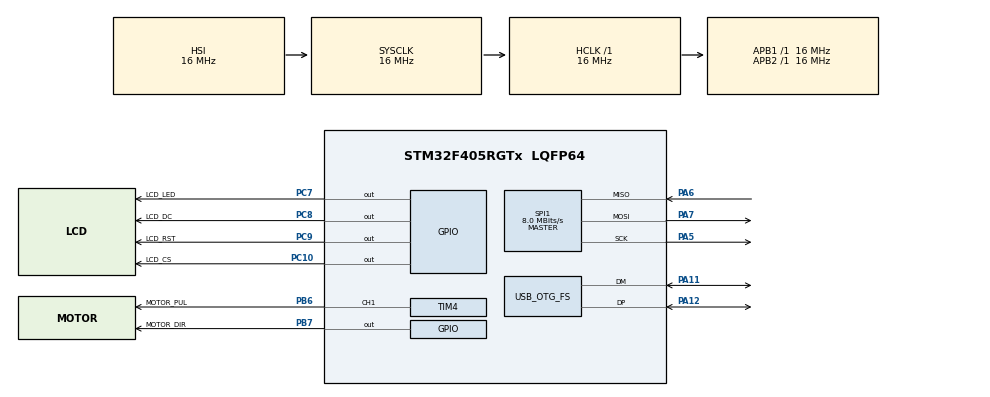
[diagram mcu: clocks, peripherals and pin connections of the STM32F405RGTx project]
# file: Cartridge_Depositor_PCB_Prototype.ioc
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Mcu.Family=STM32F4
TIM4.Channel-PWM\ Generation1\ CH1=TIM_CHANNEL_1
PA6.Mode=Full_Duplex_Master
USB_DEVICE.CLASS_NAME_FS=CDC
PH0-OSC_IN.Signal=RCC_OSC_IN
RCC.CortexFreq_Value=16000000
PA7.Mode=Full_Duplex_Master
PC10.GPIO_Label=LCD_CS
SPI1.VirtualType=VM_MASTER
PC9.GPIO_Label=LCD_RST
USB_DEVICE.VirtualModeFS=Cdc_FS
PC10.Signal=GPIO_Output
PC8.Signal=GPIO_Output
PA11.Mode=Device_Only
PB6.GPIO_Label=MOTOR_PUL
USB_DEVICE.VirtualMode-CDC_FS=Cdc
ProjectManager.StackSize=0x400
PC8.GPIO_Label=LCD_DC
PA13.Signal=SYS_JTMS-SWDIO
PA12.Signal=USB_OTG_FS_DP
ProjectManager.TargetToolchain=STM32CubeIDE
SPI1.Direction=SPI_DIRECTION_2LINES
RCC.HCLKFreq_Value=16000000
VP_USB_DEVICE_VS_USB_DEVICE_CDC_FS.Mode=CDC_FS
RCC.APB2TimFreq_Value=16000000
TIM4.Pulse-PWM\ Generation1\ CH1=50-1
PB6.Signal=S_TIM4_CH1
PC7.Signal=GPIO_Output
SPI1.CalculateBaudRate=8.0 MBits/s
TIM4.Prescaler=80-1
RCC.LSE_VALUE=32768
RCC.AHBFreq_Value=16000000
PH0-OSC_IN.Mode=HSE-External-Oscillator
PA5.Signal=SPI1_SCK
RCC.HSE_VALUE=25000000
board=custom
RCC.VCOOutputFreq_Value=240000000
RCC.APB2Freq_Value=16000000
SPI1.Mode=SPI_MODE_MASTER
PA14.Mode=Serial_Wire
PC7.PinState=GPIO_PIN_SET
PH1-OSC_OUT.Signal=RCC_OSC_OUT
PB7.Signal=GPIO_Output
TIM4.Period=50-1
PA13.Mode=Serial_Wire
Mcu.Name=STM32F405RGTx
PC7.GPIO_Label=LCD_LED
PH1-OSC_OUT.Mode=HSE-External-Oscillator
PB7.GPIO_Label=MOTOR_DIR
RCC.48MHZClocksFreq_Value=48000000
RCC.SYSCLKFreq_VALUE=16000000
Mcu.Package=LQFP64
PA6.Signal=SPI1_MISO
PA12.Mode=Device_Only
NVIC.OTG_FS_IRQn=true\:0\:0\:false\:false\:true\:false\:true
PA11.Signal=USB_OTG_FS_DM
PA14.Signal=SYS_JTCK-SWCLK
USB_OTG_FS.VirtualMode=Device_Only
ProjectManager.HeapSize=0x200
RCC.HSI_VALUE=16000000
VP_TIM4_VS_ClockSourceINT.Mode=Internal
RCC.PLLQ=5
NVIC.PriorityGroup=NVIC_PRIORITYGROUP_4
RCC.PLLM=15
RCC.PLLN=144
SH.S_TIM4_CH1.0=TIM4_CH1,PWM Generation1 CH1
RCC.APB1TimFreq_Value=16000000
PC9.Signal=GPIO_Output
RCC.APB1Freq_Value=16000000
PA5.Mode=Full_Duplex_Master
PA7.Signal=SPI1_MOSI

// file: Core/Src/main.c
/* USER CODE BEGIN Header */
/**
  ******************************************************************************
  * @file           : main.c
  * @brief          : Main program body
  ******************************************************************************
  * @attention
  *
  * <h2><center>&copy; Copyright (c) 2021 STMicroelectronics.
  * All rights reserved.</center></h2>
  *
  * This software component is licensed by ST under BSD 3-Clause license,
  * the "License"; You may not use this file except in compliance with the
  * License. You may obtain a copy of the License at:
  *                        opensource.org/licenses/BSD-3-Clause
  *
  ******************************************************************************
  */
/* USER CODE END Header */
#include "main.h"
#include "usb_device.h"

/* USER CODE BEGIN Includes */
#include "MY_ILI9341.h"
#include "TSC2046.h"
#include "Gui.h"
#include "motor_driver.h"
/* USER CODE END Includes */

/* USER CODE BEGIN PM */
#define CAL_MODE 0

/* USER CODE END PM */

SPI_HandleTypeDef hspi1;

TIM_HandleTypeDef htim4;

void SystemClock_Config(void);
static void MX_GPIO_Init(void);
static void MX_SPI1_Init(void);
static void MX_TIM4_Init(void);

int main(void)
{

  /* MCU Configuration--------------------------------------------------------*/

  /* Reset of all peripherals, Initializes the Flash interface and the Systick. */
  HAL_Init();
uint8_t i;

  /* Configure the system clock */
  SystemClock_Config();

  /* Initialize all configured peripherals */
  MX_GPIO_Init();
  MX_SPI1_Init();
  MX_USB_DEVICE_Init();
  MX_TIM4_Init();
  /* USER CODE BEGIN 2 */
  ILI9341_Init(&hspi1, LCD_CS_GPIO_Port, LCD_CS_Pin, LCD_DC_GPIO_Port, LCD_DC_Pin, LCD_RST_GPIO_Port, LCD_RST_Pin);
  HAL_GPIO_WritePin(LCD_LED_GPIO_Port, LCD_LED_Pin, 1); //Keeps screen on
  ILI9341_setRotation(1); //Rotation vertical, pins at top
  //TSC2046_Begin(&hspi2, TS_CS_GPIO_Port, TS_CS_Pin);
  ILI9341_Fill(COLOR_BLUE);
  ILI9341_printText("Hello World", 20, 40, COLOR_WHITE, COLOR_BLACK, 2);
  HAL_GPIO_WritePin(MOTOR_DIR_GPIO_Port, MOTOR_DIR_Pin, GPIO_PIN_RESET); //Initialize motor direction to CW
  HAL_TIM_PWM_Start(&htim4, TIM_CHANNEL_1); //Start motor pulse

  /* USER CODE END 2 */

  /*
  if(CAL_MODE)
    {
    TSC2046_Calibrate();
    ILI9341_Fill(COLOR_WHITE);
    Print_Cal_Vals();
    }
  else
  	{
  	Set_Cal_Vals();
  	}
  */

  /* Infinite loop */
  while (1)
  {

    /* USER CODE BEGIN 3 */
	Manual_Mode();

  }
  /* USER CODE END 3 */
}

void SystemClock_Config(void)
{
  RCC_OscInitTypeDef RCC_OscInitStruct = {0};
  RCC_ClkInitTypeDef RCC_ClkInitStruct = {0};

  /** Configure the main internal regulator output voltage
  */
  __HAL_RCC_PWR_CLK_ENABLE();
  __HAL_PWR_VOLTAGESCALING_CONFIG(PWR_REGULATOR_VOLTAGE_SCALE1);
  /** Initializes the RCC Oscillators according to the specified parameters
  * in the RCC_OscInitTypeDef structure.
  */
  RCC_OscInitStruct.OscillatorType = RCC_OSCILLATORTYPE_HSI|RCC_OSCILLATORTYPE_HSE;
  RCC_OscInitStruct.HSEState = RCC_HSE_ON;
  RCC_OscInitStruct.HSIState = RCC_HSI_ON;
  RCC_OscInitStruct.HSICalibrationValue = RCC_HSICALIBRATION_DEFAULT;
  RCC_OscInitStruct.PLL.PLLState = RCC_PLL_ON;
  RCC_OscInitStruct.PLL.PLLSource = RCC_PLLSOURCE_HSE;
  RCC_OscInitStruct.PLL.PLLM = 15;
  RCC_OscInitStruct.PLL.PLLN = 144;
  RCC_OscInitStruct.PLL.PLLP = RCC_PLLP_DIV2;
  RCC_OscInitStruct.PLL.PLLQ = 5;
  if (HAL_RCC_OscConfig(&RCC_OscInitStruct) != HAL_OK)
  {
    Error_Handler();
  }
  /** Initializes the CPU, AHB and APB buses clocks
  */
  RCC_ClkInitStruct.ClockType = RCC_CLOCKTYPE_HCLK|RCC_CLOCKTYPE_SYSCLK
                              |RCC_CLOCKTYPE_PCLK1|RCC_CLOCKTYPE_PCLK2;
  RCC_ClkInitStruct.SYSCLKSource = RCC_SYSCLKSOURCE_HSI;
  RCC_ClkInitStruct.AHBCLKDivider = RCC_SYSCLK_DIV1;
  RCC_ClkInitStruct.APB1CLKDivider = RCC_HCLK_DIV1;
  RCC_ClkInitStruct.APB2CLKDivider = RCC_HCLK_DIV1;

  if (HAL_RCC_ClockConfig(&RCC_ClkInitStruct, FLASH_LATENCY_0) != HAL_OK)
  {
    Error_Handler();
  }
}

static void MX_SPI1_Init(void)
{

  /* SPI1 parameter configuration*/
  hspi1.Instance = SPI1;
  hspi1.Init.Mode = SPI_MODE_MASTER;
  hspi1.Init.Direction = SPI_DIRECTION_2LINES;
  hspi1.Init.DataSize = SPI_DATASIZE_8BIT;
  hspi1.Init.CLKPolarity = SPI_POLARITY_LOW;
  hspi1.Init.CLKPhase = SPI_PHASE_1EDGE;
  hspi1.Init.NSS = SPI_NSS_SOFT;
  hspi1.Init.BaudRatePrescaler = SPI_BAUDRATEPRESCALER_2;
  hspi1.Init.FirstBit = SPI_FIRSTBIT_MSB;
  hspi1.Init.TIMode = SPI_TIMODE_DISABLE;
  hspi1.Init.CRCCalculation = SPI_CRCCALCULATION_DISABLE;
  hspi1.Init.CRCPolynomial = 10;
  if (HAL_SPI_Init(&hspi1) != HAL_OK)
  {
    Error_Handler();
  }

}

static void MX_TIM4_Init(void)
{

  TIM_ClockConfigTypeDef sClockSourceConfig = {0};
  TIM_MasterConfigTypeDef sMasterConfig = {0};
  TIM_OC_InitTypeDef sConfigOC = {0};

  htim4.Instance = TIM4;
  htim4.Init.Prescaler = 80-1;
  htim4.Init.CounterMode = TIM_COUNTERMODE_UP;
  htim4.Init.Period = 50-1;
  htim4.Init.ClockDivision = TIM_CLOCKDIVISION_DIV1;
  htim4.Init.AutoReloadPreload = TIM_AUTORELOAD_PRELOAD_DISABLE;
  if (HAL_TIM_Base_Init(&htim4) != HAL_OK)
  {
    Error_Handler();
  }
  sClockSourceConfig.ClockSource = TIM_CLOCKSOURCE_INTERNAL;
  if (HAL_TIM_ConfigClockSource(&htim4, &sClockSourceConfig) != HAL_OK)
  {
    Error_Handler();
  }
  if (HAL_TIM_PWM_Init(&htim4) != HAL_OK)
  {
    Error_Handler();
  }
  sMasterConfig.MasterOutputTrigger = TIM_TRGO_RESET;
  sMasterConfig.MasterSlaveMode = TIM_MASTERSLAVEMODE_DISABLE;
  if (HAL_TIMEx_MasterConfigSynchronization(&htim4, &sMasterConfig) != HAL_OK)
  {
    Error_Handler();
  }
  sConfigOC.OCMode = TIM_OCMODE_PWM1;
  sConfigOC.Pulse = 50-1;
  sConfigOC.OCPolarity = TIM_OCPOLARITY_HIGH;
  sConfigOC.OCFastMode = TIM_OCFAST_DISABLE;
  if (HAL_TIM_PWM_ConfigChannel(&htim4, &sConfigOC, TIM_CHANNEL_1) != HAL_OK)
  {
    Error_Handler();
  }
  HAL_TIM_MspPostInit(&htim4);

}

static void MX_GPIO_Init(void)
{
  GPIO_InitTypeDef GPIO_InitStruct = {0};

  /* GPIO Ports Clock Enable */
  __HAL_RCC_GPIOH_CLK_ENABLE();
  __HAL_RCC_GPIOA_CLK_ENABLE();
  __HAL_RCC_GPIOC_CLK_ENABLE();
  __HAL_RCC_GPIOB_CLK_ENABLE();

  /*Configure GPIO pin Output Level */
  HAL_GPIO_WritePin(LCD_LED_GPIO_Port, LCD_LED_Pin, GPIO_PIN_SET);

  /*Configure GPIO pin Output Level */
  HAL_GPIO_WritePin(GPIOC, LCD_DC_Pin|LCD_RST_Pin|LCD_CS_Pin, GPIO_PIN_RESET);

  /*Configure GPIO pin Output Level */
  HAL_GPIO_WritePin(MOTOR_DIR_GPIO_Port, MOTOR_DIR_Pin, GPIO_PIN_RESET);

  /*Configure GPIO pins : LCD_LED_Pin LCD_DC_Pin LCD_RST_Pin LCD_CS_Pin */
  GPIO_InitStruct.Pin = LCD_LED_Pin|LCD_DC_Pin|LCD_RST_Pin|LCD_CS_Pin;
  GPIO_InitStruct.Mode = GPIO_MODE_OUTPUT_PP;
  GPIO_InitStruct.Pull = GPIO_NOPULL;
  GPIO_InitStruct.Speed = GPIO_SPEED_FREQ_LOW;
  HAL_GPIO_Init(GPIOC, &GPIO_InitStruct);

  /*Configure GPIO pin : MOTOR_DIR_Pin */
  GPIO_InitStruct.Pin = MOTOR_DIR_Pin;
  GPIO_InitStruct.Mode = GPIO_MODE_OUTPUT_PP;
  GPIO_InitStruct.Pull = GPIO_NOPULL;
  GPIO_InitStruct.Speed = GPIO_SPEED_FREQ_LOW;
  HAL_GPIO_Init(MOTOR_DIR_GPIO_Port, &GPIO_InitStruct);

}

void Error_Handler(void)
{
  __disable_irq();
  while (1)
  {
  }
}

/************************ (C) COPYRIGHT STMicroelectronics *****END OF FILE****/
